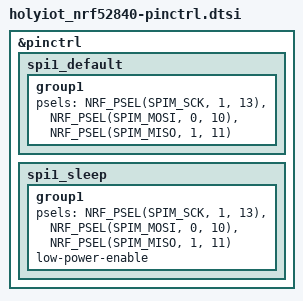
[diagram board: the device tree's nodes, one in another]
/*
 * Copyright (c) 2022 The ZMK Contributors
 * SPDX-License-Identifier: MIT
 */

&pinctrl {
    
    spi1_default: spi1_default {
        group1 {
            psels = <NRF_PSEL(SPIM_SCK, 1, 13)>,
                <NRF_PSEL(SPIM_MOSI, 0, 10)>,
                <NRF_PSEL(SPIM_MISO, 1, 11)>;
        };
    };

    spi1_sleep: spi1_sleep {
        group1 {
            psels = <NRF_PSEL(SPIM_SCK, 1, 13)>,
                <NRF_PSEL(SPIM_MOSI, 0, 10)>,
                <NRF_PSEL(SPIM_MISO, 1, 11)>;
            low-power-enable;
        };
    };
};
